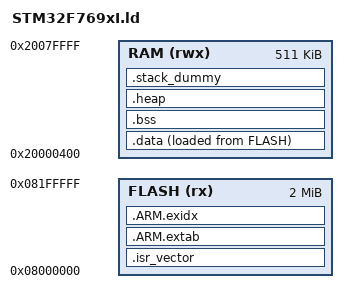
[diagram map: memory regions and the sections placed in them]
/* Linker script to configure memory regions. */
MEMORY
{ 
  FLASH (rx) : ORIGIN = 0x08000000, LENGTH = 2048K
  RAM (rwx)  : ORIGIN = 0x20000400, LENGTH = 512K - 1K
}

/* Linker script to place sections and symbol values. Should be used together
 * with other linker script that defines memory regions FLASH and RAM.
 * It references following symbols, which must be defined in code:
 *   Reset_Handler : Entry of reset handler
 * 
 * It defines following symbols, which code can use without definition:
 *   __exidx_start
 *   __exidx_end
 *   __etext
 *   __data_start__
 *   __preinit_array_start
 *   __preinit_array_end
 *   __init_array_start
 *   __init_array_end
 *   __fini_array_start
 *   __fini_array_end
 *   __data_end__
 *   __bss_start__
 *   __bss_end__
 *   __end__
 *   end
 *   __HeapLimit
 *   __StackLimit
 *   __StackTop
 *   __stack
 *   _estack
 */

/* 
 * The entry point is informative, for debuggers and simulators,
 * since the Cortex-M vector points to it anyway.
 */
ENTRY(_crt0)

SECTIONS
{

    /* For the STM32F7 the ISR vector contains the entry point */
    .isr_vector :
    {
        KEEP(*(.isr_vector))
        *(.text*)

    } > FLASH







    /* ARM magic sections */
    .ARM.extab :
    {
        *(.ARM.extab* .gnu.linkonce.armextab.*)
    } > FLASH

    __exidx_start = .;
    .ARM.exidx :
    {
        *(.ARM.exidx* .gnu.linkonce.armexidx.*)
    } > FLASH
    __exidx_end = .;


    __etext = .;





    __data_lma_start = .;


    .data : ALIGN(4)
    {
        __data_vma_start = .;
        *(.data*)

        . = ALIGN(4);
        /* preinit data */
        PROVIDE_HIDDEN (__preinit_array_start = .);
        KEEP(*(.preinit_array))
        PROVIDE_HIDDEN (__preinit_array_end = .);

        . = ALIGN(4);
        /* init data */
        PROVIDE_HIDDEN (__init_array_start = .);
        KEEP(*(SORT(.init_array.*)))
        KEEP(*(.init_array))
        PROVIDE_HIDDEN (__init_array_end = .);


        . = ALIGN(4);
        /* finit data */
        PROVIDE_HIDDEN (__fini_array_start = .);
        KEEP(*(SORT(.fini_array.*)))
        KEEP(*(.fini_array))
        PROVIDE_HIDDEN (__fini_array_end = .);

        . = ALIGN(4);
        __data_vma_end = .;

    } > RAM AT>FLASH

    __data_end = .;





    .bss :
    {
        __bss_vma_start = .;
        . = ALIGN(4);
        *(.bss*)
        *(COMMON)
        . = ALIGN(4);
        __bss_vma_end = .;
    } > RAM





    .heap (COPY):
    {
        __end__ = .;
        end = __end__;
        *(.heap*)
        __HeapLimit = .;
    } > RAM





    /* .stack_dummy section doesn't contains any symbols. It is only
     * used for linker to calculate size of stack sections, and assign
     * values to stack symbols later */
    .stack_dummy (COPY):
    {
        *(.stack*)
    } > RAM




    /* Set stack top to end of RAM, and stack limit move down by
     * size of stack_dummy section */
    _estack = ORIGIN(RAM) + LENGTH(RAM);
    __StackLimit = _estack - SIZEOF(.stack_dummy);
    PROVIDE(__stack = _estack);




    /* Check if data + heap + stack exceeds RAM limit */
    ASSERT(__StackLimit >= __HeapLimit, "region RAM overflowed with stack")
}
